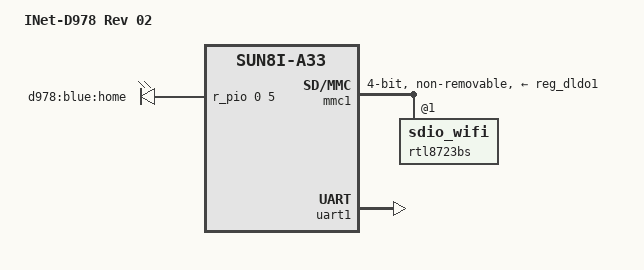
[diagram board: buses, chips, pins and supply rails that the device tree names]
/dts-v1/;
#include "sun8i-a33.dtsi"
#include "sun8i-reference-design-tablet.dtsi"
/ {
	model = "INet-D978 Rev 02";
	compatible = "primux,inet-d978-rev2", "allwinner,sun8i-a33";
	aliases {
		serial0 = &uart1;
	};
	chosen {
		/delete-property/stdout-path;
	};
	leds {
		compatible = "gpio-leds";
		pinctrl-names = "default";
		pinctrl-0 = <&led_pin_d978>;
		led {
			label = "d978:blue:home";
			gpios = <&r_pio 0 5 GPIO_ACTIVE_HIGH>;  
		};
	};
};
&mmc1 {
	pinctrl-names = "default";
	pinctrl-0 = <&mmc1_pg_pins>;
	vmmc-supply = <&reg_dldo1>;
	bus-width = <4>;
	non-removable;
	status = "okay";
	rtl8723bs: sdio_wifi@1 {
		reg = <1>;
	};
};
&r_pio {
	led_pin_d978: led-pin {
		pins = "PL5";
		function = "gpio_out";
		drive-strength = <20>;
	};
};
&r_uart {
	status = "disabled";
};
&uart1 {
	pinctrl-names = "default";
	pinctrl-0 = <&uart1_pg_pins>,
		    <&uart1_cts_rts_pg_pins>;
	status = "okay";
};
